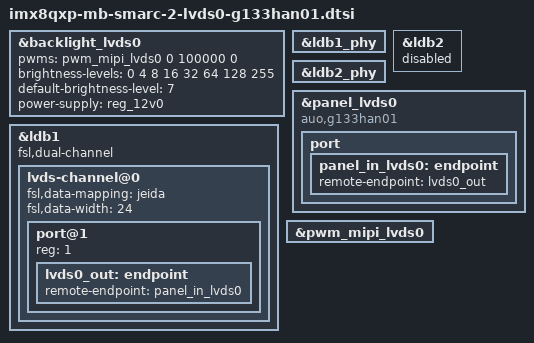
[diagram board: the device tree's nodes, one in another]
// SPDX-License-Identifier: (GPL-2.0-or-later OR MIT)
/*
 * Copyright 2020 TQ-Systems GmbH
 */

&backlight_lvds0 {
	pwms = <&pwm_mipi_lvds0 0 100000 0>;
	brightness-levels = <0 4 8 16 32 64 128 255>;
	default-brightness-level = <7>;
	power-supply = <&reg_12v0>;
	status = "okay";
};

&ldb1_phy {
	status = "okay";
};

&ldb1 {
	fsl,dual-channel;
	status = "okay";

	lvds-channel@0 {
		fsl,data-mapping = "jeida";
		fsl,data-width = <24>;
		status = "okay";

		port@1 {
			reg = <1>;

			lvds0_out: endpoint {
				remote-endpoint = <&panel_in_lvds0>;
			};
		};
	};
};

&ldb2 {
	status = "disabled";
};

&ldb2_phy {
	status = "okay";
};

&panel_lvds0 {
	compatible = "auo,g133han01";
	status = "okay";

	port {
		panel_in_lvds0: endpoint {
			remote-endpoint = <&lvds0_out>;
		};
	};
};

&pwm_mipi_lvds0 {
	status = "okay";
};
